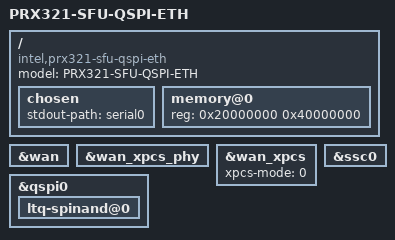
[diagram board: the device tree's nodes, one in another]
/dts-v1/;
#include "prx321-sfu-12.dtsi"

/ {
	model = "PRX321-SFU-QSPI-ETH";
	compatible = "intel,prx321-sfu-qspi-eth", "intel,prx321-sfu", "intel,prx300";

	chosen {
		stdout-path = "serial0";
	};

	memory@0 {
		device_type = "memory";
		reg = <0x20000000 0x40000000>; /* 1024 MB */
	};
};

&wan {
	status = "okay";
};

&wan_xpcs_phy {
	status = "okay";
};

&wan_xpcs {
	status = "okay";
	xpcs-mode = <0>; /* 0 - 10G_KR_MODE, 1 - 10G_XAUI_MODE, 2 - 1G_XAUI_MODE, 3 - 2P5G_GMII_MODE */
};

/* For voice enable the SPI driver needed for access to the on silicon VCODEC but prevent switching the pinmux to this SPI bus. On this design these pins are used for the QSPI bus. */
&ssc0 {
	status = "okay";
	/delete-property/ pinctrl-names;
	/delete-property/ pinctrl-0;
};

&qspi0 {
	status = "okay";
	ltq-spinand@0 {
		status = "okay";
	};
};
